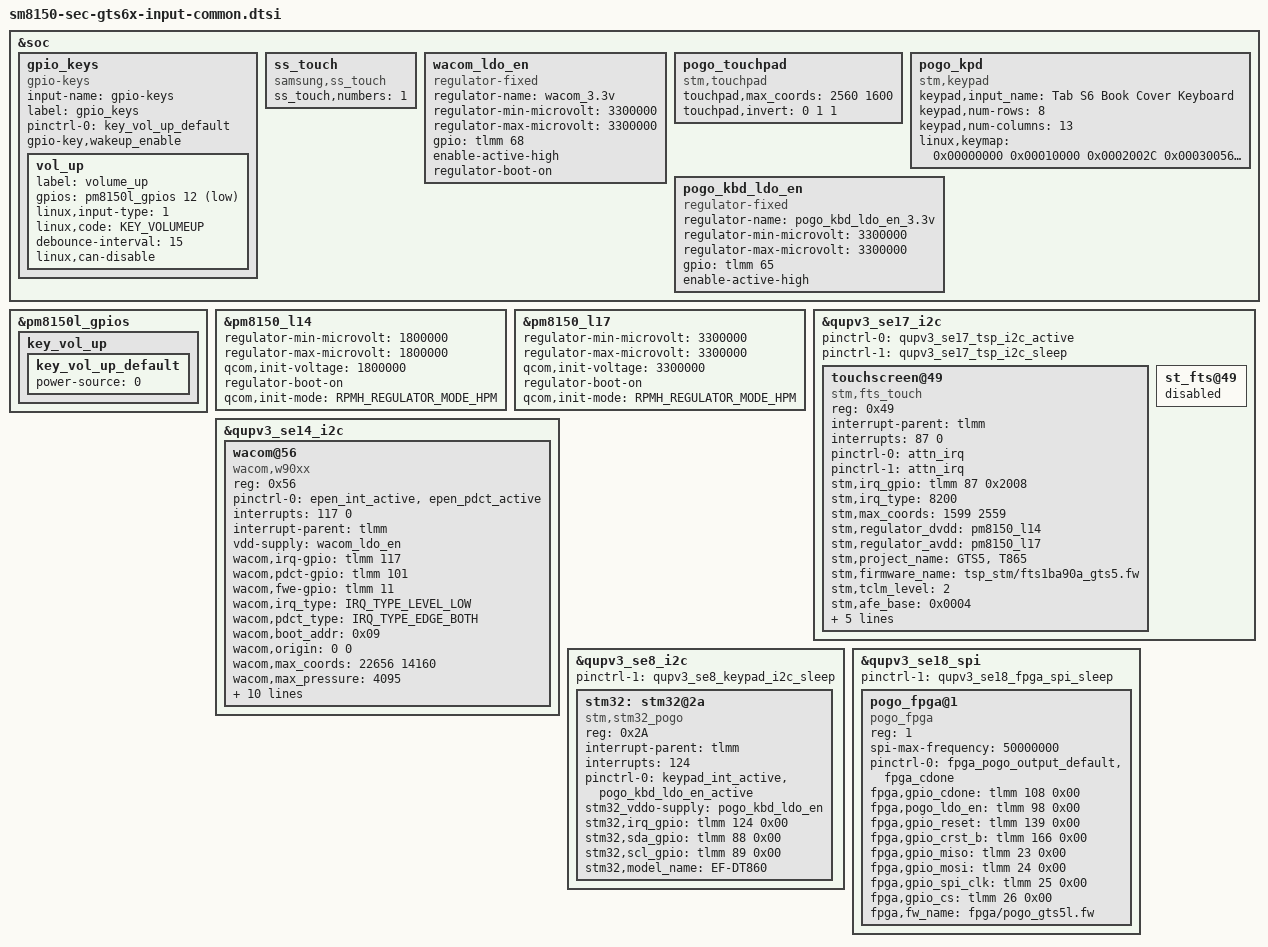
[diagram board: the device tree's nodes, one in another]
/* Copyright (c) 2016-2017, The Linux Foundation. All rights reserved.
 *
 * This program is free software; you can redistribute it and/or modify
 * it under the terms of the GNU General Public License version 2 and
 * only version 2 as published by the Free Software Foundation.
 *
 * This program is distributed in the hope that it will be useful,
 * but WITHOUT ANY WARRANTY; without even the implied warranty of
 * MERCHANTABILITY or FITNESS FOR A PARTICULAR PURPOSE.  See the
 * GNU General Public License for more details.
 */

#include <dt-bindings/input/input.h>
#include <dt-bindings/interrupt-controller/irq.h>
#include <dt-bindings/gpio/gpio.h>

/delete-node/ &gpio_keys;
&soc {
	gpio_keys: gpio_keys {
		status = "ok";
		compatible = "gpio-keys";
		input-name = "gpio-keys";
		label = "gpio_keys";

		pinctrl-names = "default";
		pinctrl-0 = <&key_vol_up_default>;
		gpio-key,wakeup_enable;

		vol_up {
			label = "volume_up";
			gpios = <&pm8150l_gpios 12 GPIO_ACTIVE_LOW>;
			linux,input-type = <1>;
			linux,code = <KEY_VOLUMEUP>;
			debounce-interval = <15>;
			linux,can-disable;
		};
	};

	ss_touch {
		compatible = "samsung,ss_touch";
		ss_touch,numbers = <1>;
	};

	wacom_ldo_en: wacom_ldo_en {
		compatible = "regulator-fixed";
		regulator-name = "wacom_3.3v";
		regulator-min-microvolt = <3300000>;
		regulator-max-microvolt = <3300000>;
		gpio = <&tlmm 68 0>;
		enable-active-high;
		regulator-boot-on;
	};

	pogo_touchpad {
		compatible = "stm,touchpad";
		touchpad,max_coords = <2560 1600>;	/* x y */
		touchpad,invert = <0 1 1>; /* x invert, y invert, xy switch */
	};

	pogo_kpd {
		compatible = "stm,keypad";
		keypad,input_name = "Tab S6 Book Cover Keyboard";
		keypad,num-rows = <8>;
		keypad,num-columns = <13>;	//  row   colume   keycode
		linux,keymap = <0x00000000	//   0       0     KEY_RESERVED		0
				0x00010000	//   0       1     KEY_RESERVED		0
				0x0002002C	//   0       2     KEY_Z		44
				0x00030056	//   0       3     KEY_102ND		86// UK KEY
				0x0004002F	//   0       4     KEY_V		47
				0x00050032	//   0       5     KEY_M		50
				0x0006006C	//   0       6     KEY_DOWN		108
				0x00070000	//   0       7     KEY_RESERVED		0
				0x00080039	//   0       8     KEY_SPACE		57
				0x00090067	//   0       9     KEY_UP		103
				0x000A0001	//   0       10    KEY_ESC		1
				0x000B0042	//   0       11    KEY_F8		66
				0x000C02C2	//   0       12    SIP_ON_OFF		706

				0x0100007D	//   1       0     KEY_LEFTMETA		125
				0x010101D0	//   1       1     KEY_FN		464
				0x0102001E	//   1       2     KEY_A		30
				0x0103002D	//   1       3     KEY_X		45
				0x01040030	//   1       4     KEY_B		48
				0x01050031	//   1       5     KEY_N		49
				0x01060033	//   1       6     KEY_COMMA		51	
				0x01070034	//   1       7     KEY_DOT		52
				0x01080035	//   1       8     KEY_SLASH		53
				0x0109001B	//   1       9     KEY_RIGHTBRACE	27
				0x010A003B	//   1       10    KEY_F1		59
				0x010B0043	//   1       11    KEY_F9		67
				0x010C0066	//   1       12    KEY_HOME		102

				0x02000000	//   2       0     KEY_RESERVED		0
				0x0201007A	//   2       1     KEY_HANGEUL		122
				0x02020010	//   2       2     KEY_Q		16
				0x0203001F	//   2       3     KEY_S		31
				0x02040021	//   2       4     KEY_F		33
				0x02050024	//   2       5     KEY_J		36
				0x02060025	//   2       6     KEY_K		37
				0x02070026	//   2       7     KEY_L		38
				0x02080027	//   2       8     KEY_SEMICOLON	39
				0x0209001C	//   2       9     KEY_ENTER		28
				0x020A003C	//   2       10    KEY_F2		60
				0x020B0044	//   2       11    KEY_F10		68
				0x020C0068	//   2       12    KEY_PAGEUP		104

				0x03000000	//   3       0     KEY_RESERVED		0
				0x03010038	//   3       1     KEY_LEFTALT		56
				0x0302000F	//   3       2     KEY_TAB		15
				0x03030011	//   3       3     KEY_W		17
				0x03040022	//   3       4     KEY_G		34
				0x03050023	//   3       5     KEY_H		35
				0x03060017	//   3       6     KEY_I		23
				0x03070028	//   3       7     KEY_APOSTROPHE	40
				0x03080019	//   3       8     KEY_P		25
				0x0309002B	//   3       9     KEY_BACKSLASH	43// UK KEY
				0x030A003D	//   3       10    KEY_F3		61
				0x030B0057	//   3       11    KEY_F11		87
				0x030C006D	//   3       12    KEY_PAGEDOWN		109

				0x0400003A	//   4       0     KEY_CAPSLOCK		58
				0x04010064	//   4       1     KEY_RIGHTALT		100
				0x04020002	//   4       2     KEY_1		2
				0x04030003	//   4       3     KEY_2		3
				0x04040013	//   4       4     KEY_R		19
				0x04050016	//   4       5     KEY_U		22
				0x04060009	//   4       6     KEY_8		9
				0x04070018	//   4       7     KEY_O		24
				0x0408000B	//   4       8     KEY_0		11
				0x0409002B	//   4       9     KEY_BACKSLASH	43
				0x040A003E	//   4       10    KEY_F4		62
				0x040B0058	//   4       11    KEY_F12		88
				0x040C006B	//   4       12    KEY_END		107

				0x05000000	//   5       0     KEY_RESERVED		0
				0x0501001D	//   5       1     KEY_CTRL		29
				0x05020029	//   5       2     KEY_GRAVE		41
				0x0503006A	//   5       3     KEY_RIGHT		106
				0x05040014	//   5       4     KEY_T		20
				0x05050015	//   5       5     KEY_Y		21
				0x05060000	//   5       6     KEY_RESERVED		0
				0x0507001A	//   5       7     KEY_LEFTBRACE	26
				0x0508000E	//   5       8     KEY_BACKSPACE	14
				0x0509000C	//   5       9     KEY_MINUS		12
				0x050A003F	//   5       10    KEY_F5		63
				0x050B02BD	//   5       11    KEY_DEX_ON		701
				0x050C0000	//   5       12    KEY_RESERVED		0

				0x06000036	//   6       0     KEY_RIGHTSHIFT	54
				0x06010069	//   6       1     KEY_LEFT		105
				0x06020020	//   6       2     KEY_D		32
				0x0603002E	//   6       3     KEY_C		46
				0x06040005	//   6       4     KEY_4		5
				0x06050008	//   6       5     KEY_7		8
				0x06060000	//   6       6     KEY_RESERVED		0
				0x0607000A	//   6       7     KEY_9		10
				0x06080004	//   6       8     KEY_3		4
				0x06090012	//   6       9     KEY_E		18
				0x060A0040	//   6       10    KEY_F6		64
				0x060B006F	//   6       11    KEY_DELETE		111
				0x060C0000	//   6       12    KEY_RESERVED		0

				0x0700002A	//   7       0     KEY_LEFTSHIFT	42
				0x07010000	//   7       1     KEY_RESERVED		0
				0x07020000	//   7       2     KEY_RESERVED		0
				0x07030000	//   7       3     KEY_RESERVED		0
				0x07040006	//   7       4     KEY_5		6
				0x07050000	//   7       5     KEY_RESERVED		0
				0x07060007	//   7       6     KEY_6		7
				0x0707000D	//   7       7     KEY_EQUAL		13
				0x07080000	//   7       8     KEY_RESERVED		0
				0x07090000	//   7       9     KEY_RESERVED		0
				0x070A0041	//   7       10    KEY_F7		65
				0x070B0214	//   7       11    KEY_TOUCHPAD_OFF	532
				0x070C0213>;	//   7       12    KEY_TOUCHPAD_ON	531
	};

	pogo_kbd_ldo_en: pogo_kbd_ldo_en {
		compatible = "regulator-fixed";
		regulator-name = "pogo_kbd_ldo_en_3.3v";
		regulator-min-microvolt = <3300000>;
		regulator-max-microvolt = <3300000>;
		gpio = <&tlmm 65 0>;
		enable-active-high;
	};
};

&pm8150l_gpios {
	key_vol_up {
		key_vol_up_default: key_vol_up_default {
			power-source = <0>;
		};
	};
};

&pm8150_l14 {
	regulator-min-microvolt = <1800000>;
	regulator-max-microvolt = <1800000>;
	qcom,init-voltage = <1800000>;
	regulator-boot-on;
	qcom,init-mode = <RPMH_REGULATOR_MODE_HPM>;
};

&pm8150_l17 {
	regulator-min-microvolt = <3300000>;
	regulator-max-microvolt = <3300000>;
	qcom,init-voltage = <3300000>;
	regulator-boot-on;
	qcom,init-mode = <RPMH_REGULATOR_MODE_HPM>;
};

&qupv3_se17_i2c {
	pinctrl-0 = <&qupv3_se17_tsp_i2c_active>;
	pinctrl-1 = <&qupv3_se17_tsp_i2c_sleep>;
	status = "ok";

	/* stm */
	touchscreen@49 {
		status = "okay";
		compatible = "stm,fts_touch";
		reg = <0x49>;
		interrupt-parent = <&tlmm>;
		interrupts = <87 0>;
		pinctrl-names = "on_state", "off_state";
		pinctrl-0 = <&attn_irq>;
		pinctrl-1 = <&attn_irq>;
		stm,irq_gpio = <&tlmm 87 0x2008>;
		stm,irq_type = <8200>;
		stm,max_coords = <1599 2559>;	/* x y */
		stm,regulator_dvdd = "pm8150_l14";
		stm,regulator_avdd = "pm8150_l17";
		stm,project_name = "GTS5", "T865";
		stm,firmware_name = "tsp_stm/fts1ba90a_gts5.fw";
		stm,tclm_level = <2>;
		stm,afe_base = <0x0004>;
		stm,enable_settings_aot;
		support_dex_mode;
		stm,ss_touch_num = <1>;
		stm,enable_vbus_noti;
		stm,support_fod;
	};

	st_fts@49 {
		status = "disabled";
	};
};

&qupv3_se14_i2c {
	status = "ok";

	wacom@56 {
		compatible = "wacom,w90xx";
		reg = <0x56>;
		pinctrl-names = "default";
		pinctrl-0 = <&epen_int_active &epen_pdct_active>;
		interrupts = <117 0>;
		interrupt-parent = <&tlmm>;
		vdd-supply = <&wacom_ldo_en>;
		/* gpios */
		wacom,irq-gpio = <&tlmm 117 0>;
		wacom,pdct-gpio = <&tlmm 101 0>;
		wacom,fwe-gpio = <&tlmm 11 0>;
		wacom,irq_type = <IRQ_TYPE_LEVEL_LOW>;
		wacom,pdct_type = <IRQ_TYPE_EDGE_BOTH>;
		/* features */
		wacom,boot_addr = <0x09>;
		wacom,origin = <0 0>; /* x y */
		wacom,max_coords = <22656 14160>; /* x y */
		wacom,max_pressure = <4095>;
		wacom,max_tilt = <63 63>;
		wacom,max_height = <255>;
		wacom,invert = <0 1 1>; /* x y switch */
		wacom,ic_type = <9021>;
		wacom,fw_path = "epen/w9021_gts6x.fw";
		wacom,fw_force_update_from = <0x4020>;
		wacom,module_ver = <0x2>; /* this value use to distinguish open/short test (0x1 : only open test, 0x2: open/short test) */
		wacom,support_aop_mode = "1"; /* S-note want to check to use aop */
		wacom,use_garage;
		wacom,table_swap = <0x2>; /* bit set: 0 ~ 1(kbd) 1(dex station)*/
	};
};

&qupv3_se8_i2c {
	status = "ok";
	pinctrl-1 = <&qupv3_se8_keypad_i2c_sleep>;

	/* pogo i2c */
	stm32:stm32@2a {
		status = "ok";
		compatible = "stm,stm32_pogo";
		reg = <0x2A>;
		interrupt-parent = <&tlmm>;
		interrupts = <124>;
		pinctrl-names = "default";
		pinctrl-0 = <&keypad_int_active &pogo_kbd_ldo_en_active>;
		stm32_vddo-supply = <&pogo_kbd_ldo_en>;
		stm32,irq_gpio = <&tlmm 124 0x00>;
		stm32,sda_gpio = <&tlmm 88 0x00>;
		stm32,scl_gpio = <&tlmm 89 0x00>;
		stm32,model_name = "EF-DT860";
	};
};

&qupv3_se18_spi {
	status = "ok";
	pinctrl-1 = <&qupv3_se18_fpga_spi_sleep>;

	pogo_fpga@1 {
		compatible = "pogo_fpga";
		reg = <1>;
		spi-max-frequency = <50000000>;
		pinctrl-names = "default";
		pinctrl-0 = <&fpga_pogo_output_default &fpga_cdone>;

		fpga,gpio_cdone = <&tlmm 108 0x00>;
		fpga,pogo_ldo_en = <&tlmm 98 0x00>;
		fpga,gpio_reset = <&tlmm 139 0x00>;
		fpga,gpio_crst_b = <&tlmm 166 0x00>;
		fpga,gpio_miso = <&tlmm 23 0x00>;
		fpga,gpio_mosi = <&tlmm 24 0x00>;
		fpga,gpio_spi_clk = <&tlmm 25 0x00>;
		fpga,gpio_cs = <&tlmm 26 0x00>;
		fpga,fw_name = "fpga/pogo_gts5l.fw";
	};
};
